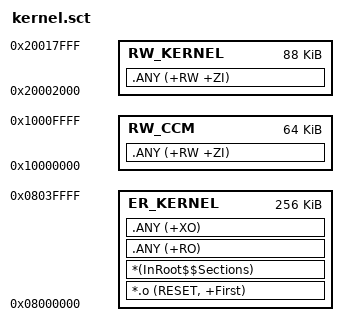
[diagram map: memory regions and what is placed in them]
; *************************************************************
; ***  本文件由 tools/gen_scatter.py 自动生成，请勿手工编辑  ***
; ***  配置源头: config/svcrt_partition.h                    ***
; ***  修改布局请改配置头，然后重新编译（编译前会自动重新生成） ***
; *************************************************************

LR_KERNEL 0x08000000 0x00040000  {
  ER_KERNEL 0x08000000 0x00040000  {
   *.o (RESET, +First)          ; 启动入口向量表必须位于分区首地址
   *(InRoot$$Sections)
   .ANY (+RO)
   .ANY (+XO)
  }
  RW_KERNEL 0x20002000 0x00016000  {
   .ANY (+RW +ZI)
  }
  RW_CCM 0x10000000 0x00010000  {   ; CCM/TCM 快速 RAM
   .ANY (+RW +ZI)
  }
}
